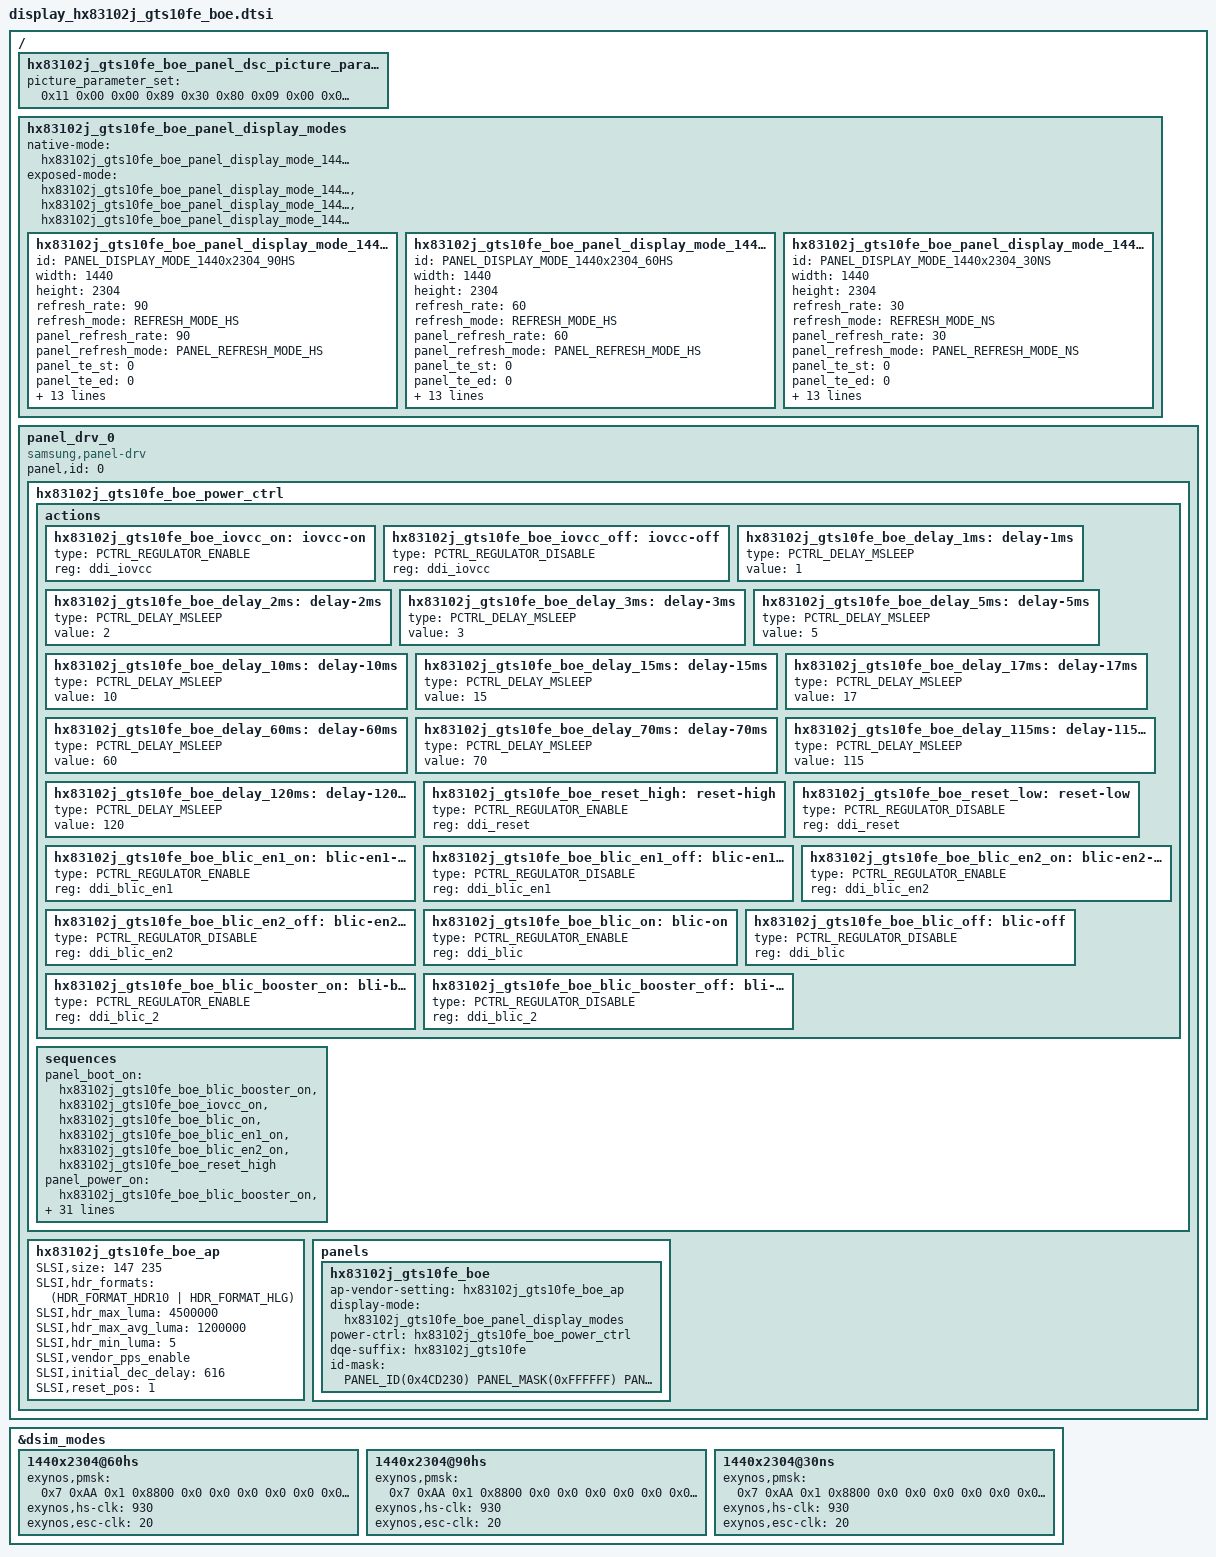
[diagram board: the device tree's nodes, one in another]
/*
 * Samsung Exynos SoC series Panel driver
 *
 * Copyright (c) 2020 Samsung Electronics Co., Ltd
 *
 * This program is free software; you can redistribute it and/or modify
 * it under the terms of the GNU General Public License version 2 as
 * published by the Free Software Foundation.
 */

#include <dt-bindings/display/panel-display.h>
#include <dt-bindings/display/exynos-display.h>

&dsim_modes {
	1440x2304@60hs {
		exynos,pmsk = <
			0x7 0xAA 0x1 0x8800 /* p m s k */
			0x0 0x0 0x0 0x0
			0x0 0x0 0x0 0x0
			0x0 0x0
			>;
		exynos,hs-clk = <930>;
		exynos,esc-clk = <20>;
	};
	1440x2304@90hs {
		exynos,pmsk = <
			0x7 0xAA 0x1 0x8800 /* p m s k */
			0x0 0x0 0x0 0x0
			0x0 0x0 0x0 0x0
			0x0 0x0
			>;
		exynos,hs-clk = <930>;
		exynos,esc-clk = <20>;
	};
	1440x2304@30ns {
		exynos,pmsk = <
			0x7 0xAA 0x1 0x8800 /* p m s k */
			0x0 0x0 0x0 0x0
			0x0 0x0 0x0 0x0
			0x0 0x0
			>;
		exynos,hs-clk = <930>;
		exynos,esc-clk = <20>;
	};
};



/ {
	fragment@panel_display_mode {
		target-path = "/";
		__overlay__ {
			hx83102j_gts10fe_boe_panel_dsc_picture_parameter_set_wuxga:
			hx83102j_gts10fe_boe_panel_dsc_picture_parameter_set_wuxga {
					picture_parameter_set = /bits/ 8 <
						0x11 0x00 0x00 0x89 0x30 0x80 0x09 0x00
						0x05 0xA0 0x00 0x18 0x02 0xD0 0x02 0xD0
						0x02 0x00 0x02 0x68 0x00 0x20 0x02 0xA1
						0x00 0x0A 0x00 0x0C 0x04 0x2D 0x03 0x2E
						0x18 0x00 0x10 0xF0 0x03 0x0C 0x20 0x00
						0x06 0x0B 0x0B 0x33 0x0E 0x1C 0x2A 0x38
						0x46 0x54 0x62 0x69 0x70 0x77 0x79 0x7B
						0x7D 0x7E 0x01 0x02 0x01 0x00 0x09 0x40
						0x09 0xBE 0x19 0xFC 0x19 0xFA 0x19 0xF8
						0x1A 0x38 0x1A 0x78 0x1A 0xB6 0x2A 0xF6
						0x2B 0x34 0x2B 0x74 0x3B 0x74 0x6B 0xF4
						0x00 0x00 0x00 0x00 0x00 0x00 0x00 0x00
						0x00 0x00 0x00 0x00 0x00 0x00 0x00 0x00
						0x00 0x00 0x00 0x00 0x00 0x00 0x00 0x00
						0x00 0x00 0x00 0x00 0x00 0x00 0x00 0x00
						0x00 0x00 0x00 0x00 0x00 0x00 0x00 0x00
					>;
			};
		
			hx83102j_gts10fe_boe_panel_display_modes:
			hx83102j_gts10fe_boe_panel_display_modes {
				native-mode = <&hx83102j_gts10fe_boe_panel_display_mode_1440x2304_90hs>;
				exposed-mode = <
					&hx83102j_gts10fe_boe_panel_display_mode_1440x2304_90hs
					&hx83102j_gts10fe_boe_panel_display_mode_1440x2304_60hs
					&hx83102j_gts10fe_boe_panel_display_mode_1440x2304_30ns
				>;

				hx83102j_gts10fe_boe_panel_display_mode_1440x2304_90hs:
				hx83102j_gts10fe_boe_panel_display_mode_1440x2304_90hs {
					id = PANEL_DISPLAY_MODE_1440x2304_90HS;
					width = <1440>;
					height = <2304>;
					/* timing parameters */
					refresh_rate = <90>;			/* logical refresh rate */
					refresh_mode = <REFRESH_MODE_HS>;
					panel_refresh_rate = <90>;		/* panel internal refresh rate */
					panel_refresh_mode = <PANEL_REFRESH_MODE_HS>;
					panel_te_st = <0>;				/* te rising */
					panel_te_ed = <0>;				/* te falling */
					panel_te_sw_skip_count = <0>;	/* s/w te modulation */
					panel_te_hw_skip_count = <0>;	/* h/w te modulation */
					/* dsc parameters */
					dsc_en = <1>;			/* 0:Disable, 1:Enable */
					dsc_cnt = <2>;			/* used DSC count */
					dsc_slice_num = <2>;	/* count of dsc slice */
					dsc_slice_w = <720>;	/* width of dsc slice */
					dsc_slice_h = <24>;	/* height of dsc slice */
					dsc_picture_parameter_set = <&hx83102j_gts10fe_boe_panel_dsc_picture_parameter_set_wuxga>;
					/* video mode parameters */
					panel_video_mode;
					panel_h_porch = <40 172 20>;
					panel_v_porch = <12 96 8>;
					/* dsi parameters */
					cmd_lp_ref = <3959>;
				};

				hx83102j_gts10fe_boe_panel_display_mode_1440x2304_60hs:
				hx83102j_gts10fe_boe_panel_display_mode_1440x2304_60hs {
					id = PANEL_DISPLAY_MODE_1440x2304_60HS;
					width = <1440>;
					height = <2304>;
					/* timing parameters */
					refresh_rate = <60>;			/* logical refresh rate */
					refresh_mode = <REFRESH_MODE_HS>;
					panel_refresh_rate = <60>;		/* panel internal refresh rate */
					panel_refresh_mode = <PANEL_REFRESH_MODE_HS>;
					panel_te_st = <0>;				/* te rising */
					panel_te_ed = <0>;				/* te falling */
					panel_te_sw_skip_count = <0>;	/* s/w te modulation */
					panel_te_hw_skip_count = <0>;	/* h/w te modulation */
					/* dsc parameters */
					dsc_en = <1>;			/* 0:Disable, 1:Enable */
					dsc_cnt = <2>;			/* used DSC count */
					dsc_slice_num = <2>;	/* count of dsc slice */
					dsc_slice_w = <720>;	/* width of dsc slice */
					dsc_slice_h = <24>;	/* height of dsc slice */
					dsc_picture_parameter_set = <&hx83102j_gts10fe_boe_panel_dsc_picture_parameter_set_wuxga>;
					/* video mode parameters */
					panel_video_mode;
					panel_h_porch = <40 172 20>;
					panel_v_porch = <12 1306 8>;
					/* dsi parameters */
					cmd_lp_ref = <3959>;
				};
				hx83102j_gts10fe_boe_panel_display_mode_1440x2304_30ns:
				hx83102j_gts10fe_boe_panel_display_mode_1440x2304_30ns {
					id = PANEL_DISPLAY_MODE_1440x2304_30NS;
					width = <1440>;
					height = <2304>;
					/* timing parameters */
					refresh_rate = <30>;			/* logical refresh rate */
					refresh_mode = <REFRESH_MODE_NS>;
					panel_refresh_rate = <30>;		/* panel internal refresh rate */
					panel_refresh_mode = <PANEL_REFRESH_MODE_NS>;
					panel_te_st = <0>;				/* te rising */
					panel_te_ed = <0>;				/* te falling */
					panel_te_sw_skip_count = <0>;	/* s/w te modulation */
					panel_te_hw_skip_count = <0>;	/* h/w te modulation */
					/* dsc parameters */
					dsc_en = <1>;			/* 0:Disable, 1:Enable */
					dsc_cnt = <2>;			/* used DSC count */
					dsc_slice_num = <2>;	/* count of dsc slice */
					dsc_slice_w = <720>;	/* width of dsc slice */
					dsc_slice_h = <24>;	/* height of dsc slice */
					dsc_picture_parameter_set = <&hx83102j_gts10fe_boe_panel_dsc_picture_parameter_set_wuxga>;
					/* video mode parameters */
					panel_video_mode;
					panel_h_porch = <40 172 20>;
					panel_v_porch = <12 4936 8>;
					/* dsi parameters */
					cmd_lp_ref = <3959>;
				};
			};
		};
	};
};

/ {
	fragment@panel_drv {
		target-path = "/";
		__overlay__ {
			panel_drv_0: panel_drv_0 {
				status = "okay";
				compatible = "samsung,panel-drv";
				panel,id = <0>;

				hx83102j_gts10fe_boe_power_ctrl:
				hx83102j_gts10fe_boe_power_ctrl {
					actions {
						hx83102j_gts10fe_boe_iovcc_on: iovcc-on {
							type = <PCTRL_REGULATOR_ENABLE>;
							reg = <&ddi_iovcc>;
						};
						hx83102j_gts10fe_boe_iovcc_off: iovcc-off {
							type = <PCTRL_REGULATOR_DISABLE>;
							reg = <&ddi_iovcc>;
						};
						hx83102j_gts10fe_boe_delay_1ms: delay-1ms {
							type = <PCTRL_DELAY_MSLEEP>;
							value = <1>;
						};
						hx83102j_gts10fe_boe_delay_2ms: delay-2ms {
							type = <PCTRL_DELAY_MSLEEP>;
							value = <2>;
						};
						hx83102j_gts10fe_boe_delay_3ms: delay-3ms {
							type = <PCTRL_DELAY_MSLEEP>;
							value = <3>;
						};
						hx83102j_gts10fe_boe_delay_5ms: delay-5ms {
							type = <PCTRL_DELAY_MSLEEP>;
							value = <5>;
						};
						hx83102j_gts10fe_boe_delay_10ms: delay-10ms {
							type = <PCTRL_DELAY_MSLEEP>;
							value = <10>;
						};
						hx83102j_gts10fe_boe_delay_15ms: delay-15ms {
							type = <PCTRL_DELAY_MSLEEP>;
							value = <15>;
						};
						hx83102j_gts10fe_boe_delay_17ms: delay-17ms {
							type = <PCTRL_DELAY_MSLEEP>;
							value = <17>;
						};
						hx83102j_gts10fe_boe_delay_60ms: delay-60ms {
							type = <PCTRL_DELAY_MSLEEP>;
							value = <60>;
						};
						hx83102j_gts10fe_boe_delay_70ms: delay-70ms {
							type = <PCTRL_DELAY_MSLEEP>;
							value = <70>;
						};
						hx83102j_gts10fe_boe_delay_115ms: delay-115ms {
							type = <PCTRL_DELAY_MSLEEP>;
							value = <115>;
						};
						hx83102j_gts10fe_boe_delay_120ms: delay-120ms {
							type = <PCTRL_DELAY_MSLEEP>;
							value = <120>;
						};
						hx83102j_gts10fe_boe_reset_high: reset-high {
							type = <PCTRL_REGULATOR_ENABLE>;
							reg = <&ddi_reset>;
						};
						hx83102j_gts10fe_boe_reset_low: reset-low {
							type = <PCTRL_REGULATOR_DISABLE>;
							reg = <&ddi_reset>;
						};
						
						hx83102j_gts10fe_boe_blic_en1_on: blic-en1-on {
							type = <PCTRL_REGULATOR_ENABLE>;
							reg = <&ddi_blic_en1>;
						};
						hx83102j_gts10fe_boe_blic_en1_off: blic-en1-off {
							type = <PCTRL_REGULATOR_DISABLE>;
							reg = <&ddi_blic_en1>;
						};
						hx83102j_gts10fe_boe_blic_en2_on: blic-en2-on {
							type = <PCTRL_REGULATOR_ENABLE>;
							reg = <&ddi_blic_en2>;
						};
						hx83102j_gts10fe_boe_blic_en2_off: blic-en2-off {
							type = <PCTRL_REGULATOR_DISABLE>;
							reg = <&ddi_blic_en2>;
						};						
						hx83102j_gts10fe_boe_blic_on: blic-on {
							type = <PCTRL_REGULATOR_ENABLE>;
							reg = <&ddi_blic>;
						};
						hx83102j_gts10fe_boe_blic_off: blic-off {
							type = <PCTRL_REGULATOR_DISABLE>;
							reg = <&ddi_blic>;
						};
						hx83102j_gts10fe_boe_blic_booster_on: bli-booster-on {
							type = <PCTRL_REGULATOR_ENABLE>;
							reg = <&ddi_blic_2>;
						};
						hx83102j_gts10fe_boe_blic_booster_off: bli-booster-off {
							type = <PCTRL_REGULATOR_DISABLE>;
							reg = <&ddi_blic_2>;
						};
					};
					sequences {
						panel_boot_on = <
							&hx83102j_gts10fe_boe_blic_booster_on
							&hx83102j_gts10fe_boe_iovcc_on
							&hx83102j_gts10fe_boe_blic_on
							&hx83102j_gts10fe_boe_blic_en1_on
							&hx83102j_gts10fe_boe_blic_en2_on
							&hx83102j_gts10fe_boe_reset_high
						>;

						panel_power_on = <
							&hx83102j_gts10fe_boe_blic_booster_on
							&hx83102j_gts10fe_boe_delay_5ms
							&hx83102j_gts10fe_boe_iovcc_on
							&hx83102j_gts10fe_boe_delay_5ms
							&hx83102j_gts10fe_boe_blic_on
							&hx83102j_gts10fe_boe_delay_5ms
							&hx83102j_gts10fe_boe_blic_en1_on
							&hx83102j_gts10fe_boe_delay_5ms
							&hx83102j_gts10fe_boe_blic_en2_on
							&hx83102j_gts10fe_boe_delay_10ms
						>;
						panel_power_off = <
							&hx83102j_gts10fe_boe_delay_70ms
							&hx83102j_gts10fe_boe_reset_low
							&hx83102j_gts10fe_boe_delay_1ms
							&hx83102j_gts10fe_boe_blic_en2_off
							&hx83102j_gts10fe_boe_delay_2ms
							&hx83102j_gts10fe_boe_blic_en1_off
							&hx83102j_gts10fe_boe_delay_2ms
							&hx83102j_gts10fe_boe_blic_off
							&hx83102j_gts10fe_boe_delay_3ms
							&hx83102j_gts10fe_boe_blic_booster_off
							&hx83102j_gts10fe_boe_delay_5ms
							&hx83102j_gts10fe_boe_iovcc_off
							&hx83102j_gts10fe_boe_delay_115ms
						>;
						panel_reset_lp11 = <
							&hx83102j_gts10fe_boe_delay_15ms
							&hx83102j_gts10fe_boe_reset_high
							&hx83102j_gts10fe_boe_delay_2ms
							&hx83102j_gts10fe_boe_reset_low
							&hx83102j_gts10fe_boe_delay_2ms
							&hx83102j_gts10fe_boe_reset_high
							&hx83102j_gts10fe_boe_delay_17ms
						>;
					};
				};

				hx83102j_gts10fe_boe_ap: hx83102j_gts10fe_boe_ap {
					/* SLSI */
					SLSI,size = <147 235>;
					SLSI,hdr_formats = <(HDR_FORMAT_HDR10 | HDR_FORMAT_HLG)>;
					SLSI,hdr_max_luma = <4500000>;	/* 450 */
					SLSI,hdr_max_avg_luma = <1200000>;	/* 120 */
					SLSI,hdr_min_luma = <5>;		/* 0.0005 */
					/* DSC PPS vender setting (optional) */
					SLSI,vendor_pps_enable;
					SLSI,initial_dec_delay = <616>;	// 0x268
					SLSI,reset_pos = <1>; 	/* 0: LP00, 1: LP11, 2: LP11_HS(def) */
				};

				panels {
					hx83102j_gts10fe_boe: hx83102j_gts10fe_boe {
						ap-vendor-setting = <&hx83102j_gts10fe_boe_ap>;
						display-mode = <&hx83102j_gts10fe_boe_panel_display_modes>;
						power-ctrl = <&hx83102j_gts10fe_boe_power_ctrl>;
						dqe-suffix = "hx83102j_gts10fe";
						id-mask = <
							PANEL_ID(0x4CD230) PANEL_MASK(0xFFFFFF)
							PANEL_ID(0x5CD230) PANEL_MASK(0xFFFFFF)
							PANEL_ID(0x000000) PANEL_MASK(0x000000)
						>;
					};
				};
			};
		};
	};
};

